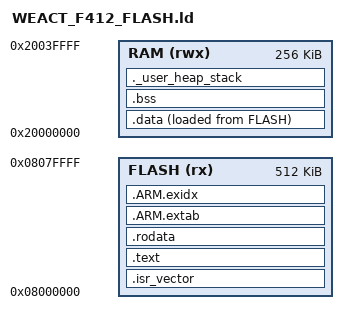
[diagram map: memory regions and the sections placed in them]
/*
 * Auto-generated by mcu-description/tools/generate.py - DO NOT EDIT BY HAND.
 * Source: mcu-description/devices/WEACT_F412.yaml
 * Regenerate: python3 mcu-description/tools/generate.py --device WEACT_F412
 */

ENTRY(Reset_Handler)

_Min_Heap_Size  = 0x400;  /* required amount of heap  */
_Min_Stack_Size = 0x400;  /* required amount of stack */

MEMORY
{
  FLASH (rx)  : ORIGIN = 0x08000000, LENGTH = 0x80000
  RAM   (rwx) : ORIGIN = 0x20000000, LENGTH = 0x40000
}

_estack = ORIGIN(RAM) + LENGTH(RAM);

SECTIONS
{
  .isr_vector :
  {
    . = ALIGN(4);
    KEEP(*(.isr_vector))
    . = ALIGN(4);
  } > FLASH

  .text :
  {
    . = ALIGN(4);
    *(.text)
    *(.text*)
    *(.glue_7)
    *(.glue_7t)
    KEEP (*(.init))
    KEEP (*(.fini))
    . = ALIGN(4);
    _etext = .;
  } > FLASH

  .rodata :
  {
    . = ALIGN(4);
    *(.rodata)
    *(.rodata*)
    . = ALIGN(4);
  } > FLASH

  .ARM.extab : { *(.ARM.extab* .gnu.linkonce.armextab.*) } > FLASH
  .ARM.exidx :
  {
    __exidx_start = .;
    *(.ARM.exidx*)
    __exidx_end = .;
  } > FLASH

  _sidata = LOADADDR(.data);

  .data :
  {
    . = ALIGN(4);
    _sdata = .;
    /* Flash operations must be run from RAM in order not to fetch instruction from the Flash array itself
       while the controller is program/erase. */
    *(.ramfunc)
    *(.ramfunc*)
    *(.data)
    *(.data*)
    . = ALIGN(4);
    _edata = .;
  } > RAM AT> FLASH

  . = ALIGN(4);
  .bss :
  {
    _sbss = .;
    *(.bss)
    *(.bss*)
    *(COMMON)
    . = ALIGN(4);
    _ebss = .;
  } > RAM

  ._user_heap_stack :
  {
    . = ALIGN(8);
    PROVIDE ( end = . );
    PROVIDE ( _end = . );
    . = . + _Min_Heap_Size;
    . = . + _Min_Stack_Size;
    . = ALIGN(8);
  } > RAM

  /DISCARD/ : { libc.a ( * ) libm.a ( * ) libgcc.a ( * ) }
}
